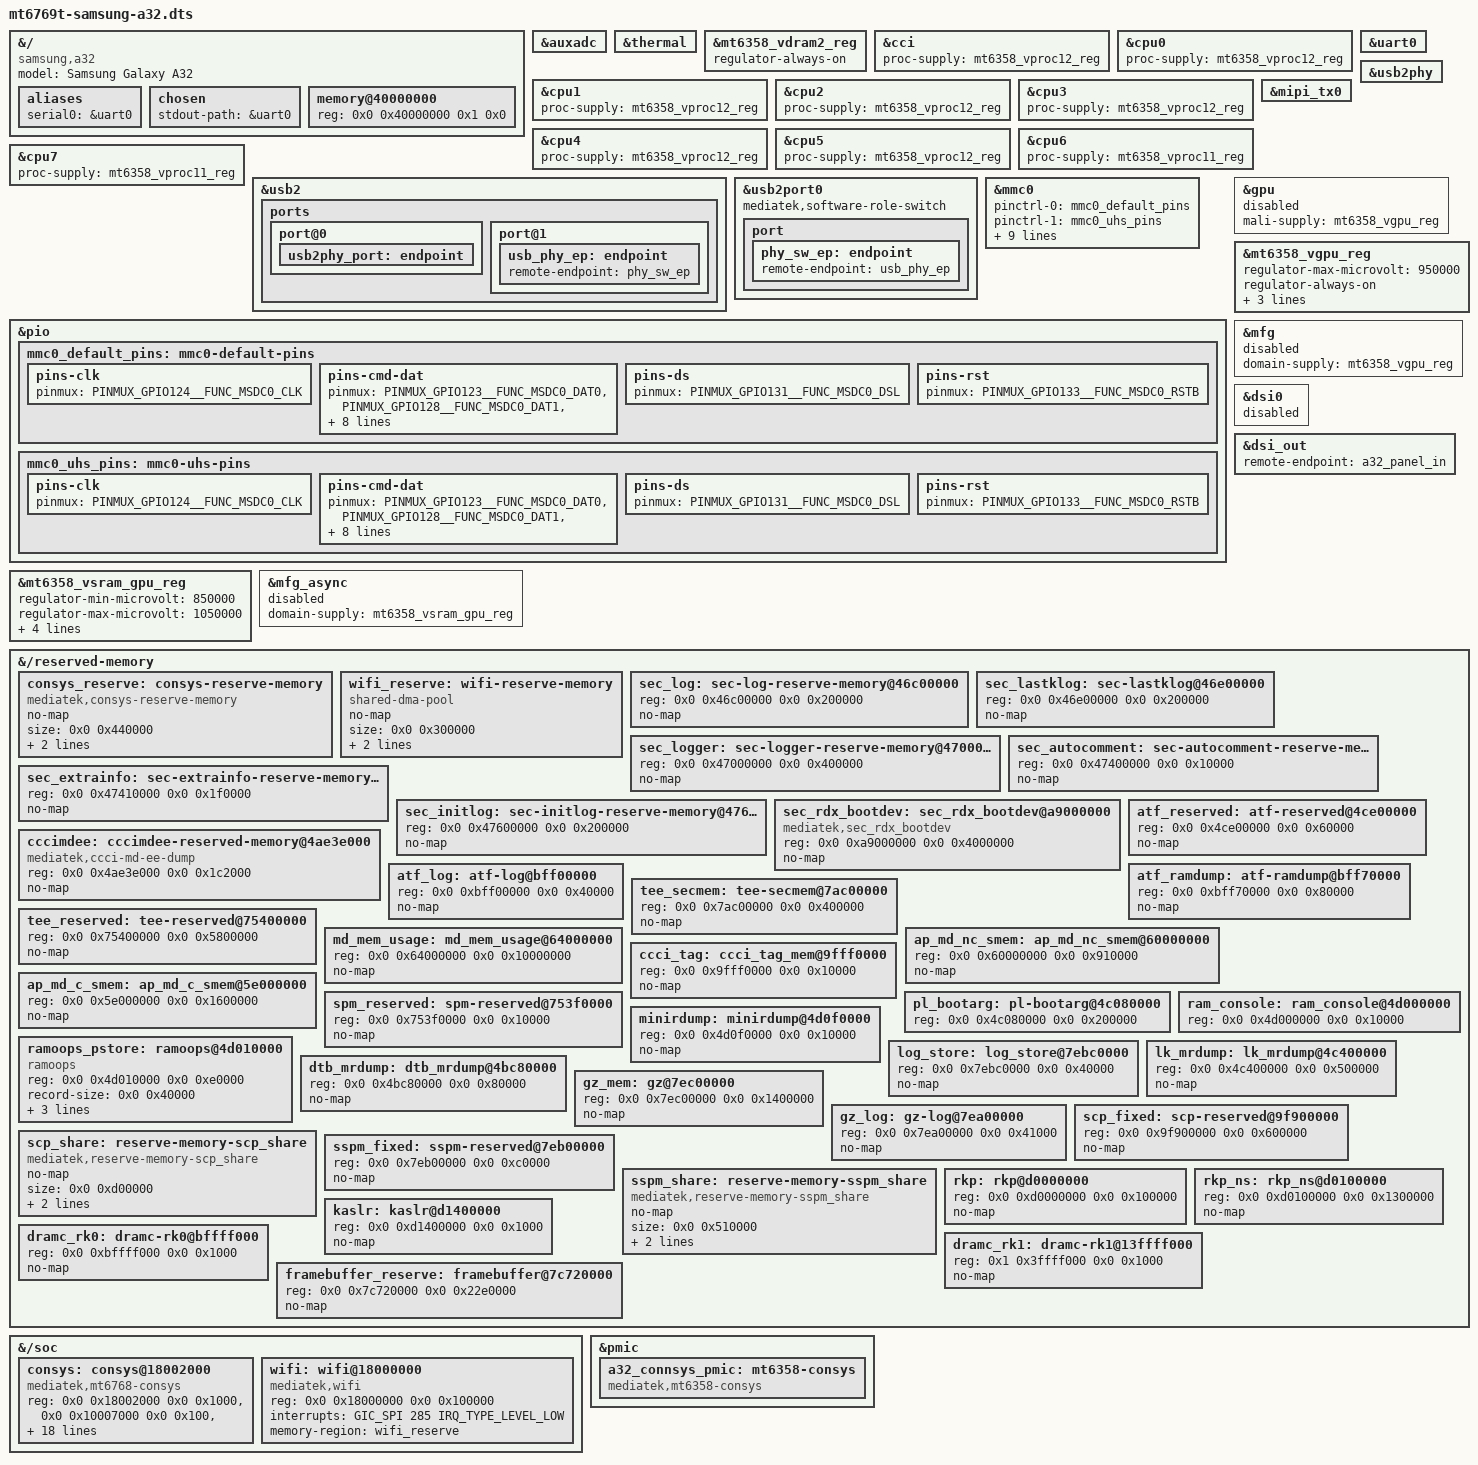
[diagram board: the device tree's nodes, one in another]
// SPDX-License-Identifier: GPL-2.0-only
/*
 * Device Tree Source for Samsung Galaxy A32 (SM-A325F, MT6768 family)
 *
 * Bring-up board file. Minimal-first: only blocks with A32 evidence are
 * enabled. Everything board-specific without evidence is OMITTED with a
 * TODO (never copied from Redmi boards).
 *
 * Tag legend (trailing comment on every board-level property):
 *   SoC-common | board-specific | vendor-derived | measured | inferred
 */

/dts-v1/;

#include <dt-bindings/gpio/gpio.h>
#include "mt6768.dtsi" /* pulls mt6768.dtsi + 1.8GHz cluster0 OPP */ /* SoC-common */
#include "mt6358.dtsi" /* MT6358 companion PMIC, measured on this unit */ /* measured */
#include "mt6769t-samsung-a32-ccci.dtsi" /* Track A: modem-ccci DISABLED until TODO-CCCI-PROBE */ /* board-specific */
#include "mt6769t-samsung-a32-bt.dtsi" /* Track B: bluetooth-a32 DISABLED until BTIF gates close */ /* board-specific */
#include "mt6769t-samsung-a32-usb.dtsi" /* USB: generic mediatek musb, usb2 ENABLED (otg) */ /* board-specific */
#include "mt6769t-samsung-a32-panel.dtsi" /* Track D: s6e3fc3 panel wiring, dsi0 ENABLED (see below) */ /* board-specific */

&{/} {
	model = "Samsung Galaxy A32"; /* board-specific */
	compatible = "samsung,a32", "mediatek,mt6769t", "mediatek,mt6768"; /* board-specific */

	aliases {
		serial0 = &uart0; /* board-specific */
	};

	chosen {
		stdout-path = &uart0; /* board-specific: serial console; framebuffer path lands here once TODO-G (LK FB addr) closes */
	};

	memory@40000000 {
		device_type = "memory"; /* SoC-common */
		/* 4GB unit: ro.boot.dram_info=4096MB + ddr_size measured; bootloader
		 * refines usable (MemTotal 3732920kB). Full 4GB described; LK trims. */
		reg = <0x0 0x40000000 0x1 0x0>; /* measured */
	};
};

&auxadc {
	status = "okay"; /* SoC-common: ADC block, no board wiring */
};

&thermal {
	status = "okay"; /* SoC-common: thermal zones via SoC sensors */
};

/* PMIC interrupt GPIO: xiaomi uses pio144 — NOT copied (board-specific, A32
 * value unknown). SoC default stands until measured. TODO-PMIC-IRQ. */

&mt6358_vdram2_reg {
	regulator-always-on; /* inferred: DRAM rail, required by memory node above */
};

&cci {
	proc-supply = <&mt6358_vproc12_reg>; /* inferred: little-cluster rail, family pattern */
};

&cpu0 {
	proc-supply = <&mt6358_vproc12_reg>; /* inferred */
};

&cpu1 {
	proc-supply = <&mt6358_vproc12_reg>; /* inferred */
};

&cpu2 {
	proc-supply = <&mt6358_vproc12_reg>; /* inferred */
};

&cpu3 {
	proc-supply = <&mt6358_vproc12_reg>; /* inferred */
};

&cpu4 {
	proc-supply = <&mt6358_vproc12_reg>; /* inferred */
};

&cpu5 {
	proc-supply = <&mt6358_vproc12_reg>; /* inferred */
};

&cpu6 {
	proc-supply = <&mt6358_vproc11_reg>; /* inferred: big-cluster rail, family pattern */
};

&cpu7 {
	proc-supply = <&mt6358_vproc11_reg>; /* inferred */
};

&uart0 {
	status = "okay"; /* board-specific: console UART */
};

/* USB: sys.usb.controller=musb-hdrc measured; musb+tphy shape. Generic
 * mainline port graph only. Redmi typec connector (willsemi,wusb3801) NOT
 * copied — A32 TCPC unknown. TODO-USB-ROLE. */
&usb2 {
	status = "okay"; /* measured */

	ports {
		#address-cells = <1>; /* SoC-common */
		#size-cells = <0>; /* SoC-common */

		port@0 {
			usb2phy_port: endpoint {
				/* remote-endpoint: typec connector, TODO-USB-ROLE */ /* board-specific */
			};
		};
		port@1 {
			usb_phy_ep: endpoint {
				remote-endpoint = <&phy_sw_ep>; /* SoC-common */
			};
		};
	};
};

&usb2port0 {
	mediatek,software-role-switch; /* inferred: role-switch until TCPC known */

	port {
		phy_sw_ep: endpoint {
			remote-endpoint = <&usb_phy_ep>; /* SoC-common */
		};
	};
};

&usb2phy {
	status = "okay"; /* measured: tphy present */
};

/* Keyboard/volume keys: merlin MATRIX_KEY VOLUMEDOWN on kprow/col0 NOT copied
 * (Redmi specifics). Server needs no keys. TODO-KEYS if ever wanted. */

&mipi_tx0 {
	status = "okay"; /* SoC-common: DSI PHY block, inert until dsi0 enabled */
};

/* eMMC: measured (11230000.msdc, mmcblk0 boot device, mtk_emmc_support=1).
 * P0 BLOCKER FIX (mtk-sd.c:3033-3048): probe does pinctrl_lookup_state for
 * "default" + "state_uhs" and hard-fails (probe abort, no eMMC) without
 * them. Both states are wired below via new &pio MSDC0 groups.
 * Mux reference: same-SoC xiaomi-common dtsi (GPIO122-133 MSDC0 funcs;
 * mt6768-pinfunc.h: PINMUX_GPIO122__FUNC_MSDC0_CMD ... _MSDC0_RSTB).
 * drive/bias are reset defaults (properties OMITTED): Redmi drive values
 * are board tuning, NOT copied. TODO-MMC-PIN: measure/verify drive on A32.
 * Conservative first-boot profile: HS/DDR52 ceiling (52MHz), no HS200, no
 * CMDQ, no HW-reset. HS200 restore ladder: docs/PHYSICAL-BOOT-GATE.md
 * TODO-MMC-HS200 (clean mmc_test + write-verify first). */
&mmc0 {
	status = "okay"; /* measured */
	pinctrl-names = "default", "state_uhs"; /* measured-blocker fix: mtk-sd.c:3033-3048 */
	pinctrl-0 = <&mmc0_default_pins>; /* same-SoC mux ref: xiaomi-common dtsi */
	pinctrl-1 = <&mmc0_uhs_pins>; /* same-SoC mux ref: xiaomi-common dtsi */
	bus-width = <8>; /* measured: eMMC (JEDEC 8-bit) */
	max-frequency = <52000000>; /* inferred: conservative HS/DDR52 first-boot ceiling (was HS200 200MHz; TODO-MMC-HS200) */
	cap-mmc-highspeed; /* SoC-common */
	mmc-ddr-1_8v; /* SoC-common */
	/* mmc-hs200-1_8v REMOVED for first boot: restore per TODO-MMC-HS200 after clean mmc_test + write-verify */
	/* cap-mmc-hw-reset REMOVED for first boot: RSTB pin defined below but reset path unproven; restore with HS200 */
	no-sdio; /* board-specific: eMMC slot, no SDIO */
	no-sd; /* board-specific: eMMC slot, no SD */
	non-removable; /* board-specific: soldered eMMC */
	/* supports-cqe REMOVED for first boot: no CMDQ until HS200 proven; restore with HS200 */
	vmmc-supply = <&mt6358_vemc_reg>; /* vendor-derived: eMMC power rail, family pattern */
	vqmmc-supply = <&mt6358_vio18_reg>; /* vendor-derived: eMMC IO rail, family pattern */
};

/* MSDC0 pin groups (P0 blocker fix, see &mmc0 above). Same-SoC mux
 * reference only (xiaomi-common dtsi): GPIO122 CMD, GPIO123/128/125/132/
 * 126/129/127/130 DAT0-7, GPIO124 CLK, GPIO131 DSL, GPIO133 RSTB
 * (mt6768-pinfunc.h MSDC0 funcs). drive/bias OMITTED = reset defaults;
 * default and uhs groups are intentionally identical until TODO-MMC-PIN
 * measures A32 drive requirements (xiaomi points both states at default;
 * we keep two labels so the uhs state exists for the mtk-sd lookup). */
&pio {
	mmc0_default_pins: mmc0-default-pins {
		pins-clk {
			pinmux = <PINMUX_GPIO124__FUNC_MSDC0_CLK>; /* same-SoC mux ref */
		};

		pins-cmd-dat {
			pinmux = <PINMUX_GPIO123__FUNC_MSDC0_DAT0>, /* same-SoC mux ref */
				 <PINMUX_GPIO128__FUNC_MSDC0_DAT1>, /* same-SoC mux ref */
				 <PINMUX_GPIO125__FUNC_MSDC0_DAT2>, /* same-SoC mux ref */
				 <PINMUX_GPIO132__FUNC_MSDC0_DAT3>, /* same-SoC mux ref */
				 <PINMUX_GPIO126__FUNC_MSDC0_DAT4>, /* same-SoC mux ref */
				 <PINMUX_GPIO129__FUNC_MSDC0_DAT5>, /* same-SoC mux ref */
				 <PINMUX_GPIO127__FUNC_MSDC0_DAT6>, /* same-SoC mux ref */
				 <PINMUX_GPIO130__FUNC_MSDC0_DAT7>, /* same-SoC mux ref */
				 <PINMUX_GPIO122__FUNC_MSDC0_CMD>; /* same-SoC mux ref */
			input-enable; /* functional (DAT input), not drive tuning */
		};

		pins-ds {
			pinmux = <PINMUX_GPIO131__FUNC_MSDC0_DSL>; /* same-SoC mux ref */
		};

		pins-rst {
			pinmux = <PINMUX_GPIO133__FUNC_MSDC0_RSTB>; /* same-SoC mux ref */
		};
	};

	mmc0_uhs_pins: mmc0-uhs-pins {
		pins-clk {
			pinmux = <PINMUX_GPIO124__FUNC_MSDC0_CLK>; /* same-SoC mux ref */
		};

		pins-cmd-dat {
			pinmux = <PINMUX_GPIO123__FUNC_MSDC0_DAT0>, /* same-SoC mux ref */
				 <PINMUX_GPIO128__FUNC_MSDC0_DAT1>, /* same-SoC mux ref */
				 <PINMUX_GPIO125__FUNC_MSDC0_DAT2>, /* same-SoC mux ref */
				 <PINMUX_GPIO132__FUNC_MSDC0_DAT3>, /* same-SoC mux ref */
				 <PINMUX_GPIO126__FUNC_MSDC0_DAT4>, /* same-SoC mux ref */
				 <PINMUX_GPIO129__FUNC_MSDC0_DAT5>, /* same-SoC mux ref */
				 <PINMUX_GPIO127__FUNC_MSDC0_DAT6>, /* same-SoC mux ref */
				 <PINMUX_GPIO130__FUNC_MSDC0_DAT7>, /* same-SoC mux ref */
				 <PINMUX_GPIO122__FUNC_MSDC0_CMD>; /* same-SoC mux ref */
			input-enable; /* functional (DAT input), not drive tuning */
		};

		pins-ds {
			pinmux = <PINMUX_GPIO131__FUNC_MSDC0_DSL>; /* same-SoC mux ref */
		};

		pins-rst {
			pinmux = <PINMUX_GPIO133__FUNC_MSDC0_RSTB>; /* same-SoC mux ref */
		};
	};
};

/* mmc1 (SD slot): merlin cd-gpios pio18 NOT copied (Redmi-specific).
 * A32 slot presence + card-detect GPIO unknown. OMITTED. TODO-SD. */

/* STORAGE-FIRST SMOKE TEST (reversible): GPU/MFG gated so a display/GPU
 * fault can never mask eMMC/R1 diagnosis on first boot. Re-enable path:
 * flip &gpu + &mfg_async + &mfg below back to "okay" together (all three;
 * MFG domains default off with no consumer) once mmcblk0 + RNDIS-SSH are
 * proven. Documented in docs/FIRST-BOOT-OBSERVABILITY.md. */
&gpu {
	status = "disabled"; /* board-specific: storage-first gate (was okay; inferred G52 present) */
	mali-supply = <&mt6358_vgpu_reg>; /* inferred: family pattern (xiaomi-common:208) */
};

&mt6358_vgpu_reg {
	regulator-max-microvolt = <950000>; /* inferred: family pattern (xiaomi-common:212) */
	regulator-always-on; /* inferred */
	regulator-boot-on; /* inferred */

	regulator-coupled-with = <&mt6358_vsram_gpu_reg>; /* inferred: family pattern */
	regulator-coupled-max-spread = <100000>; /* inferred: family pattern */
};

&mt6358_vsram_gpu_reg {
	regulator-min-microvolt = <850000>; /* inferred: family pattern */
	regulator-max-microvolt = <1050000>; /* inferred: family pattern */
	regulator-always-on; /* inferred */
	regulator-boot-on; /* inferred */

	regulator-coupled-with = <&mt6358_vgpu_reg>; /* inferred: family pattern */
	regulator-coupled-max-spread = <100000>; /* inferred: family pattern */
};

&mfg_async {
	status = "disabled"; /* board-specific: storage-first gate, re-enable with &gpu (see above) */
	domain-supply = <&mt6358_vsram_gpu_reg>; /* inferred: family pattern */
};

&mfg {
	status = "disabled"; /* board-specific: storage-first gate, re-enable with &gpu (see above) */
	domain-supply = <&mt6358_vgpu_reg>; /* inferred: family pattern */
};

/* DSI + panel (Track D merge): the FAIL-SAFE STUB
 * (compatible "samsung,a32-panel-stub") is DELETED here and replaced by the
 * real entry from mt6769t-samsung-a32-panel.dtsi (included above), per that
 * fragment's MERGE INSTRUCTION: stub node removed, #address-cells/#size-cells
 * and panel@0 (compatible "samsung,s6e3fc3-a32", LCD_RST=pio45,
 * LCD_1P8_EN=pio25, LCD_3P0_EN=pio153) come from the fragment.
 * STORAGE-FIRST SMOKE TEST (reversible): &dsi0 gated to "disabled" so
 * panel/GPU cannot mask eMMC/R1 diagnosis on first boot; the panel@0 child
 * is inert while its parent is disabled (driver + binding stay in tree).
 * Re-enable path: flip &dsi0 back to "okay" once mmcblk0 + RNDIS-SSH are
 * proven (TODO-PANEL hardware proof still required regardless).
 * Integration states: dsi0/panel GATED (storage-first); modem-ccci DISABLED;
 * bluetooth-a32 DISABLED; usb2 musb ENABLED. */
&dsi0 {
	status = "disabled"; /* board-specific: storage-first gate (was okay per Track D merge) */
};

&dsi_out {
	remote-endpoint = <&a32_panel_in>; /* SoC-common */
};

/* Connsys board power/clock/EMI path (W4-connsys). Scope: THIS block only.
 * Every value tagged: vendor-derived = downstream mt6768 DTB reverse
 * (build/downstream/out/.../mt6768.dtb.reverse.dts, read-only evidence);
 * SoC-common = already in mt6768.dtsi/mt6358.dtsi; inferred = mainline
 * integration with the exact consumer cited (no invented IDs).
 * Deliberately OMITTED (see BLOCKED list in docs/CONNINFRA-GATE.md §5):
 * clocks/clock-names (driver consumer compiled out on 6.18:
 * COMMON_KERNEL_CLK_SUPPORT=1, mt6768.h:27-29; downstream "conn" was
 * scpsys cell 1 with no mainline clock-cell provider — bus clocks ride
 * the CONN genpd instead); resets (no evidenced mt6768 CCIF reset ID on
 * mainline; downstream mt6768 has no store_reset_control — only mt6853
 * has one, wrong silicon); pinctrl/ant-swap GPIO (A32 pins unknown). */
/* PRE-FLASH RESERVE MAP (A32 evidence only; every line cites its source).
 * Stock source: Samsung 4.14 tree mt6768.dts (verbatim addrs/sizes).
 * Live source: live-reserved-map.txt (34 nodes probed on THIS phone,
 * device-backup-20261002-183552/metadata/live-android/).
 * Sanity rule applied per node: addresses must sit inside
 * 0x40000000-0x140000000 (all below do; nothing stopped).
 * Overlap rule: fixed regions verified pairwise-contiguous, not
 * overlapping (sec-log family 0x46C-0x478 contiguous; ram_console/
 * pstore/minirdump 0x4D000000-0x4D100000 contiguous; framebuffer/
 * gz-log/SSPM/log_store/gz 0x7C720000-0x80000000 contiguous).
 * TODO-MEMRSV CLOSED by this block (was: modem/scp carveouts unknown). */
&{/reserved-memory} {
	consys_reserve: consys-reserve-memory {
		compatible = "mediatek,consys-reserve-memory"; /* vendor-derived: DTB:370 */
		no-map; /* vendor-derived: DTB:371 */
		size = <0x0 0x440000>; /* vendor-derived: DTB:372 */
		alignment = <0x0 0x1000000>; /* vendor-derived: DTB:373 */
		alloc-ranges = <0x0 0x40000000 0x0 0x80000000>; /* vendor-derived: DTB:374; inside measured 4GB memory@40000000 */
	};

	wifi_reserve: wifi-reserve-memory {
		compatible = "shared-dma-pool"; /* vendor-derived: DTB:378 */
		no-map; /* vendor-derived: DTB:379 */
		size = <0x0 0x300000>; /* vendor-derived: DTB:380 */
		alignment = <0x0 0x1000000>; /* vendor-derived: DTB:381 */
		alloc-ranges = <0x0 0x40000000 0x0 0x80000000>; /* vendor-derived: DTB:382 */
	};

	/* Stock sec-log family (6 nodes, Samsung 4.14 mt6768.dts:312-336
	 * verbatim; each confirmed live at the same addr/size). no-map:
	 * firmware log agents own these; Linux must not clobber them. */
	sec_log: sec-log-reserve-memory@46c00000 {
		reg = <0x0 0x46c00000 0x0 0x200000>; /* stock:312-316 + live:18 */
		no-map; /* pre-flash safety: SEC log region */
	};

	sec_lastklog: sec-lastklog@46e00000 {
		reg = <0x0 0x46e00000 0x0 0x200000>; /* stock:318-320 + live:9 */
		no-map; /* pre-flash safety: SEC lastklog region */
	};

	sec_logger: sec-logger-reserve-memory@47000000 {
		reg = <0x0 0x47000000 0x0 0x400000>; /* stock:322-324 + live:14 */
		no-map; /* pre-flash safety: SEC logger region */
	};

	sec_autocomment: sec-autocomment-reserve-memory@47400000 {
		reg = <0x0 0x47400000 0x0 0x10000>; /* stock:326-328 + live:22 */
		no-map; /* pre-flash safety: SEC autocomment region */
	};

	sec_extrainfo: sec-extrainfo-reserve-memory@47410000 {
		reg = <0x0 0x47410000 0x0 0x1f0000>; /* stock:330-332 + live:17 */
		no-map; /* pre-flash safety: SEC extrainfo region */
	};

	sec_initlog: sec-initlog-reserve-memory@47600000 {
		reg = <0x0 0x47600000 0x0 0x200000>; /* stock:334-336 + live:8 */
		no-map; /* pre-flash safety: SEC initlog region */
	};

	/* Stock rdx_bootdev (Samsung 4.14 mt6768.dts:339-344 verbatim;
	 * stock node label says @A0000000 but reg is 0xA9000000 — label
	 * corrected to match reg; in range: 0xA9000000 < 0x140000000). */
	sec_rdx_bootdev: sec_rdx_bootdev@a9000000 {
		compatible = "mediatek,sec_rdx_bootdev"; /* stock:340 */
		reg = <0x0 0xa9000000 0x0 0x4000000>; /* stock:342 */
		no-map; /* pre-flash safety: RD dump boot device window */
	};

	/* Stock + live cccimdee (stock:362-365 verbatim; live:3 same
	 * addr/size). no-map (task-mandated; stock/live map it but the EE
	 * dump agent owns it — driver ioremaps when CCCI enables). */
	cccimdee: cccimdee-reserved-memory@4ae3e000 {
		compatible = "mediatek,ccci-md-ee-dump"; /* stock:363 + live:3 */
		reg = <0x0 0x4ae3e000 0x0 0x1c2000>; /* stock:364 + live:3 */
		no-map; /* pre-flash safety: modem EE dump region */
	};

	/* Live ATF trio (live:11,2,27; all live-flagged no-map). */
	atf_reserved: atf-reserved@4ce00000 {
		reg = <0x0 0x4ce00000 0x0 0x60000>; /* live:11 */
		no-map; /* live:11 no-map (ATF owns) */
	};

	atf_log: atf-log@bff00000 {
		reg = <0x0 0xbff00000 0x0 0x40000>; /* live:2 */
		no-map; /* live:2 no-map (ATF log) */
	};

	atf_ramdump: atf-ramdump@bff70000 {
		reg = <0x0 0xbff70000 0x0 0x80000>; /* live:27 */
		no-map; /* live:27 no-map (ATF ramdump) */
	};

	/* Live TEE pair (live:16,28; both live-flagged no-map). */
	tee_secmem: tee-secmem@7ac00000 {
		reg = <0x0 0x7ac00000 0x0 0x400000>; /* live:16 */
		no-map; /* live:16 no-map (TEE secure mem) */
	};

	tee_reserved: tee-reserved@75400000 {
		reg = <0x0 0x75400000 0x0 0x5800000>; /* live:28 */
		no-map; /* live:28 no-map (TEE reserved) */
	};

	/* Live modem trio (live:25,32,12). Live maps these (no no-map
	 * flag) for AP-side modem access; first-boot reserves them no-map
	 * for safety (CCCI driver ioremaps when TODO-CCCI-PROBE enables
	 * the transport). Documented divergence, reversible. */
	md_mem_usage: md_mem_usage@64000000 {
		reg = <0x0 0x64000000 0x0 0x10000000>; /* live:25 */
		no-map; /* pre-flash safety (live maps; see above) */
	};

	ap_md_nc_smem: ap_md_nc_smem@60000000 {
		reg = <0x0 0x60000000 0x0 0x910000>; /* live:32 */
		no-map; /* pre-flash safety (live maps; see above) */
	};

	ap_md_c_smem: ap_md_c_smem@5e000000 {
		reg = <0x0 0x5e000000 0x0 0x1600000>; /* live:12 */
		no-map; /* pre-flash safety (live maps; see above) */
	};

	ccci_tag: ccci_tag_mem@9fff0000 {
		reg = <0x0 0x9fff0000 0x0 0x10000>; /* live:6 */
		no-map; /* live:6 no-map (CCCI tag) */
	};

	/* Live SPM (live:7, no-map). Adjacent to tee-reserved
	 * (0x753F0000+0x10000 = 0x75400000) — no overlap. */
	spm_reserved: spm-reserved@753f0000 {
		reg = <0x0 0x753f0000 0x0 0x10000>; /* live:7 */
		no-map; /* live:7 no-map (SPM owns) */
	};

	/* Live pl-bootarg (live:20, live maps it — bootloader args stay
	 * readable; kept mapped). */
	pl_bootarg: pl-bootarg@4c080000 {
		reg = <0x0 0x4c080000 0x0 0x200000>; /* live:20 */
	};

	/* Live ram_console (live:1 flags no-map; kept MAPPED per bring-up
	 * decision so the kernel can read the previous-boot console log —
	 * first-boot forensics path, see FIRST-BOOT-OBSERVABILITY). */
	ram_console: ram_console@4d000000 {
		reg = <0x0 0x4d000000 0x0 0x10000>; /* live:1 */
	};

	/* Live pstore as ramoops (live:34 flags no-map; kept MAPPED:
	 * pstore/ramoops needs normal mapping to record panics. Console +
	 * record + ftrace + pmsg (0xC0000) fit inside 0xE0000. Backend is
	 * still CONFIG_PSTORE_RAM=m (module) — see observability doc. */
	ramoops_pstore: ramoops@4d010000 {
		compatible = "ramoops"; /* bring-up: pstore backend binding */
		reg = <0x0 0x4d010000 0x0 0xe0000>; /* live:34 */
		record-size = <0x0 0x40000>; /* bring-up: dmesg records */
		console-size = <0x0 0x40000>; /* bring-up: console log */
		ftrace-size = <0x0 0x20000>; /* bring-up: ftrace log */
		pmsg-size = <0x0 0x20000>; /* bring-up: pmsg log */
	};

	/* Live minirdump + log_store + mrdump pair (all no-map). log_store
	 * and dtb_mrdump are live-mapped but reserved no-map for first
	 * boot (documented divergence, reversible). */
	minirdump: minirdump@4d0f0000 {
		reg = <0x0 0x4d0f0000 0x0 0x10000>; /* live:4 */
		no-map; /* live:4 no-map */
	};

	log_store: log_store@7ebc0000 {
		reg = <0x0 0x7ebc0000 0x0 0x40000>; /* live:33 */
		no-map; /* pre-flash safety (live maps; see above) */
	};

	lk_mrdump: lk_mrdump@4c400000 {
		reg = <0x0 0x4c400000 0x0 0x500000>; /* live:29 */
		no-map; /* live:29 no-map */
	};

	dtb_mrdump: dtb_mrdump@4bc80000 {
		reg = <0x0 0x4bc80000 0x0 0x80000>; /* live:30 */
		no-map; /* pre-flash safety (live maps; see above) */
	};

	/* Live GZ pair (live:15,5; both live-flagged no-map). */
	gz_mem: gz@7ec00000 {
		reg = <0x0 0x7ec00000 0x0 0x1400000>; /* live:15 */
		no-map; /* live:15 no-map (Gunyah owns) */
	};

	gz_log: gz-log@7ea00000 {
		reg = <0x0 0x7ea00000 0x0 0x41000>; /* live:5 */
		no-map; /* live:5 no-map (GZ log) */
	};

	/* Live SCP: fixed 6MB node (live:21) PLUS the stock scp_share pool
	 * below (A32 override size 0xD00000 = 13MB). SUPERSET choice: the
	 * pool reserves the stock size (allocatable, no invented address)
	 * while the fixed node pins the live address — together they cover
	 * both claims; neither overlaps the other (pool has no fixed reg).
	 * Revisit when SCP firmware needs are measured. */
	scp_fixed: scp-reserved@9f900000 {
		reg = <0x0 0x9f900000 0x0 0x600000>; /* live:21 */
		no-map; /* live:21 no-map (SCP owns) */
	};

	scp_share: reserve-memory-scp_share {
		compatible = "mediatek,reserve-memory-scp_share"; /* stock:381 */
		no-map; /* stock:382 */
		size = <0x0 0xd00000>; /* A32 override (stock base 0x300000:383; 13MB superset) */
		alignment = <0x0 0x1000000>; /* stock:384 */
		alloc-ranges = <0x0 0x40000000 0x0 0x50000000>; /* stock:385 */
	};

	/* Live SSPM: fixed 0xC0000 node (live:13) PLUS the stock
	 * sspm_share pool below (default 0x510000; GMO 0x110000 variant
	 * noted, default taken). SUPERSET choice, same reasoning as SCP
	 * above: pool reserves the stock size, fixed node pins the live
	 * address (0x7EB00000 + live size ends 0x7EBC0000, exactly where
	 * log_store starts — contiguous, no overlap). */
	sspm_fixed: sspm-reserved@7eb00000 {
		reg = <0x0 0x7eb00000 0x0 0xc0000>; /* live:13 */
		no-map; /* live:13 no-map (SSPM owns) */
	};

	sspm_share: reserve-memory-sspm_share {
		compatible = "mediatek,reserve-memory-sspm_share"; /* stock:368 */
		no-map; /* stock:369 */
		size = <0x0 0x510000>; /* stock default:373 (GMO 0x110000 not taken) */
		alignment = <0x0 0x10000>; /* stock:375 */
		alloc-ranges = <0x0 0x40000000 0x0 0x60000000>; /* stock:376 */
	};

	/* Live RKP trio (live:10,23,26; all live-mapped, reserved no-map
	 * for first boot — hypervisor/KASLR regions; documented
	 * divergence, reversible). All inside range (0xD0000000-0xD1401000
	 * < 0x140000000). */
	rkp: rkp@d0000000 {
		reg = <0x0 0xd0000000 0x0 0x100000>; /* live:10 */
		no-map; /* pre-flash safety (live maps; see above) */
	};

	rkp_ns: rkp_ns@d0100000 {
		reg = <0x0 0xd0100000 0x0 0x1300000>; /* live:23 */
		no-map; /* pre-flash safety (live maps; see above) */
	};

	kaslr: kaslr@d1400000 {
		reg = <0x0 0xd1400000 0x0 0x1000>; /* live:26 */
		no-map; /* pre-flash safety (live maps; see above) */
	};

	/* Live dramc-rk pair (live:19,24; tiny 1-page SRAM-adjacent
	 * nodes, both live-flagged no-map). dramc-rk1 at 0x13FFFF000 is
	 * inside range (< 0x140000000). */
	dramc_rk0: dramc-rk0@bffff000 {
		reg = <0x0 0xbffff000 0x0 0x1000>; /* live:19 */
		no-map; /* live:19 no-map */
	};

	dramc_rk1: dramc-rk1@13ffff000 {
		reg = <0x1 0x3ffff000 0x0 0x1000>; /* live:24 (0x13FFFF000 = <0x1 0x3FFFF000>; 64-bit cell split, NOT truncated) */
		no-map; /* live:24 no-map */
	};

	/* Live framebuffer (live:31): RESERVE-ONLY no-map. Display is NOT
	 * enabled from it (dsi0 gated storage-first); the reserve simply
	 * stops Linux from clobbering the LK splash framebuffer. */
	framebuffer_reserve: framebuffer@7c720000 {
		reg = <0x0 0x7c720000 0x0 0x22e0000>; /* live:31 */
		no-map; /* reserve-only: LK splash preserved, display not enabled */
	};
};

&{/soc} {
	consys: consys@18002000 {
		compatible = "mediatek,mt6768-consys"; /* vendor-derived: DTB:2925; bound by apwmt_of_ids (mtk_wcn_consys_hw.c) */
		#address-cells = <2>; /* vendor-derived: DTB:2926 */
		#size-cells = <2>; /* vendor-derived: DTB:2927 */
		/* vendor-derived: DTB:2928, order = CONSYS_BASE_ADDRESS_INDEX
		 * (mtk_wcn_consys_hw.h:172-181), consumed by
		 * consys_read_reg_from_dts (of_iomap per index). */
		reg = <0x0 0x18002000 0x0 0x1000>, /* MCU_BASE_INDEX */
		      <0x0 0x10007000 0x0 0x100>, /* TOP_RGU_BASE_INDEX */
		      <0x0 0x10001000 0x0 0x1000>, /* INFRACFG_AO_BASE_INDEX */
		      <0x0 0x10006000 0x0 0x1000>, /* SPM_BASE_INDEX */
		      <0x0 0x18007000 0x0 0x1000>, /* MCU_CONN_HIF_ON_BASE_INDEX */
		      <0x0 0x180b1000 0x0 0x1000>, /* MCU_TOP_MISC_OFF_BASE_INDEX */
		      <0x0 0x180a3000 0x0 0x1000>, /* MCU_CFG_ON_BASE_INDEX */
		      <0x0 0x180a5000 0x0 0x800>, /* MCU_CIRQ_BASE_INDEX */
		      <0x0 0x180c1000 0x0 0x1000>, /* MCU_TOP_MISC_ON_BASE_INDEX */
		      <0x0 0x18004000 0x0 0x1000>; /* MCU_CONN_HIF_PDMA_BASE_INDEX */
		/* vendor-derived: DTB:2929 (GIC_SPI=0; 0x8=LEVEL_LOW, 0x1=EDGE_RISING).
		 * Index 0 = BGF eint, index 2 = conn2ap_sw_irq (dedicated log). */
		interrupts = <GIC_SPI 284 IRQ_TYPE_LEVEL_LOW>,
			     <GIC_SPI 78 IRQ_TYPE_LEVEL_LOW>,
			     <GIC_SPI 287 IRQ_TYPE_EDGE_RISING>;
		/* SoC-common providers, board-level binding: CONN genpd drives
		 * pm_runtime_get_sync(&connsys_pdev->dev) (mt6768.c:715;
		 * COMMON_KERNEL_CLK_SUPPORT=1 path). */
		power-domains = <&spm MT6768_POWER_DOMAIN_CONN>; /* SoC-common */
		/* Consumer names vendor-derived (mt6768.c:589-598) → mainline
		 * providers (mt6358.dtsi). Mainline has ONE vcn33 rail, so
		 * both split consumers share it (inferred, shared-regulator
		 * legal; voltages 1.8/2.8/3.3V match DTB:1348/1378/1510). */
		vcn18-supply = <&mt6358_vcn18_reg>; /* vendor-derived */
		vcn28-supply = <&mt6358_vcn28_reg>; /* vendor-derived */
		vcn33_bt-supply = <&mt6358_vcn33_reg>; /* inferred: shared single VCN33 */
		vcn33_wifi-supply = <&mt6358_vcn33_reg>; /* inferred: shared single VCN33 */
		/* Inferred integration: mtk_wcn_get_regmap() parses the "pmic"
		 * phandle (mtk_wcn_consys_hw.c:258); mainline mt6397-core sets
		 * drvdata to the chip (mt6397-core.c:391), so this resolves. */
		pmic = <&pmic>; /* inferred */
		/* Inferred integration: wmt_allocate_connsys_emi() parses
		 * "memory-region" (mtk_wcn_consys_hw.c:290); pool = consys
		 * 0x440000 reserve (FW patch/log/coredump EMI). */
		memory-region = <&consys_reserve>; /* inferred */
		status = "okay"; /* board-specific */
	};

	wifi: wifi@18000000 {
		compatible = "mediatek,wifi"; /* vendor-derived: DTB:3741 */
		reg = <0x0 0x18000000 0x0 0x100000>; /* vendor-derived: DTB:3742 */
		interrupts = <GIC_SPI 285 IRQ_TYPE_LEVEL_LOW>; /* vendor-derived: DTB:3743 (0x11d=285, 0x8) */
		memory-region = <&wifi_reserve>; /* vendor-derived: DTB:3744 (phandle 0x61 = wifi-reserve-memory) */
		status = "okay"; /* board-specific */
	};
};

/* PMIC regmap anchor for the connsys power path. The wmt driver registers
 * consys_pmic_mt6358_dev_drv matching "mediatek,mt6358-consys"
 * (mt6768.c:334-348) to fetch the mt6397 regmap for the OP_EN/HW-mode
 * writes. INERT on mainline until the MFD cell table gains this compatible
 * (drivers/mfd/mt6397-core.c, out of scope) — see BLOCKED item B5. The
 * regulator_enable/disable half of every vcn path works WITHOUT the
 * regmap (loud "failed to get regmap" + real regulator call). */
&pmic {
	a32_connsys_pmic: mt6358-consys {
		compatible = "mediatek,mt6358-consys"; /* vendor-derived: mt6768.c:335 */
		status = "okay"; /* board-specific */
	};
};

/* OMITTED (no A32 evidence — each a TODO, none copied from Redmi):
 * gpio-leds/flashlight (pio152/153 Redmi-specific) TODO-LEDS;
 * i2c0 KTD3137 backlight (Redmi addr/tuning) TODO-BL;
 * i2c3 NXP PN553 NFC (Redmi wiring) TODO-NFC;
 * i2c5 mt6370 charger/backlight/indicator/flashlight + dsv/vibldo (Redmi PMIC companions) TODO-PMIC2;
 * i2c7 willsemi TCPC (Redmi-specific) TODO-USB-ROLE;
 * spi0 nt36672a touch + spi3 cs35l41 amp (Redmi peripherals) TODO-TOUCH TODO-AUDIO;
 * devapc/dvfsrc enables (left at SoC default) TODO-DVFS;
 * mmc1 SD slot (cd-gpio unknown) TODO-SD.
 * CLOSED here: TODO-MEMRSV (modem/scp/TEE/ATF/log reserves from live +
 * stock evidence in &{/reserved-memory} above); TODO-MMC-PIN partially
 * (MSDC0 mux wired, drive tuning still open).
 */
